# ELM_ELM_527F0000h register map
Vendor: Texas Instruments
Peripheral module from a debugger description file (folder AM261x).
Registers are 32-bit, read-only, reset values left out (the file's numbers can be read two ways) unless marked. A register's access mark holds for its fields unless they carry their own. Offsets are as the file gives them; lines under a group give offsets from that group; [hi:lo] are bit positions; {n}, {i} and the like mark numbered series; 'fields as' and 'values as' point back to an identical list; <NAME> marks a mode.

## ELM
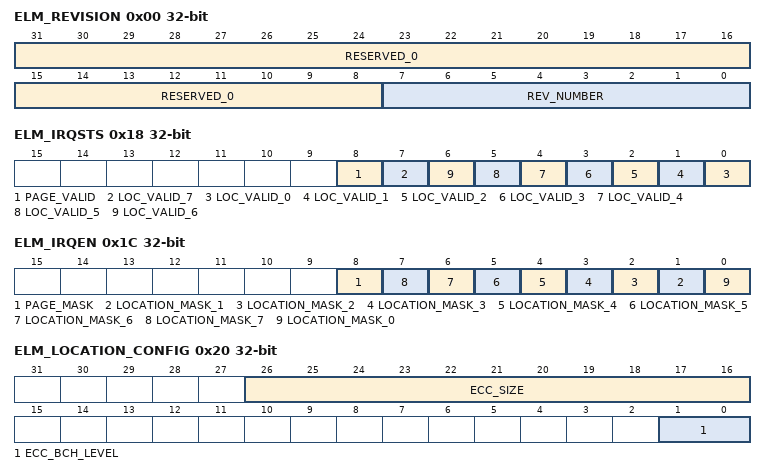
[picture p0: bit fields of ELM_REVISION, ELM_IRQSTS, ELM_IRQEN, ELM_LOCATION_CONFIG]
0x00 ELM_REVISION — This register contains the IP revision code.(A write to this register has no effect, the same as the reset).
  [31:8] RESERVED_0 — Read returns 0
  [7:0] REV_NUMBER — IP revision number [RTL] [7:4] Major revision [3:0] Minor revision
0x14 ELM_SYSSTS — Internal Reset monitoring (OCP domain)Undefined since:From HW perspective reset state is 0From SW user perspective when module is accessible is 1
  [0] RESETDONE
0x18 ELM_IRQSTS access not given — Interrupt status. This register doubles as a status register for the error location processes.
  [8] PAGE_VALID — Error location status for a full page, based on the mask definition Read 0x0: error locations invalid for all polynomials enabled in the ECC_INTERRUPT_MASK register Read 0x1: all error locations valid Write 0x0: no effect Write 0x1: clear interrupt (access R/W1TC)
  [7] LOC_VALID_7 — Error location status for syndrome polynomial 7 Read 0x0: no syndrome processed or process in progress Read 0x1: error location process completed Write 0x0: no effect Write 0x1: clear interrupt (access R/W1TC)
  [n] LOC_VALID_{n} (n=0..6) — Error location status for syndrome polynomial {n} (access R/W1TC)
0x1C ELM_IRQEN rw — Interrupt enable.
  [8] PAGE_MASK — Page interrupt mask bit0:disable interrupt1:enable interrupt
  [n] LOCATION_MASK_{n} (n=1..7) — Error location interrupt mask bit for syndrome polynomial {n}
  [0] LOCATION_MASK_0 — Error location interrupt mask bit for syndrome polynomial 00:disable interrupt1:enable interrupt
0x20 ELM_LOCATION_CONFIG rw — ECC algorithm parameters.
  [26:16] ECC_SIZE — Maximum size of the buffers for which the error location engine is used, in number of nibbles [4-bits entities]
  [1:0] ECC_BCH_LEVEL — Error correction level 0x0: 4 bits 0x1: 8 bits 0x2: 16 bits 0x3: reserved
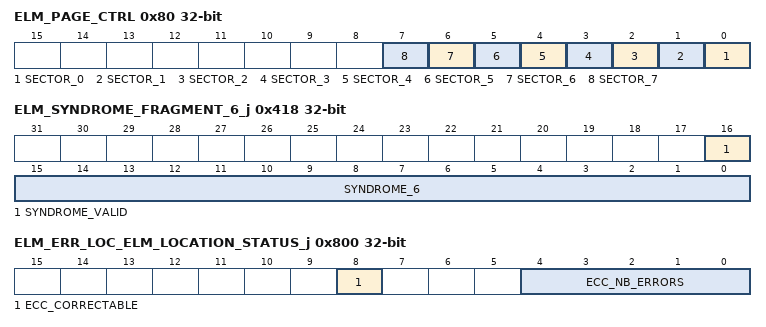
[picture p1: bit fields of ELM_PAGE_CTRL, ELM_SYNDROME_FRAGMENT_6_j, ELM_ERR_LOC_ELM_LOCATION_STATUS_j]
0x80 ELM_PAGE_CTRL rw — Page definition.
  [n] SECTOR_{n} (n=0..7) — Set to 1 if syndrome polynomial {n} is part of the page in page mode Must be 0 in continuous mode
{0x400+4i} ELM_SYNDROME_FRAGMENT_{i}_j rw (i=0..2) — Input syndrome polynomial bits {32i} to {32i+31}.
  [31:0] SYNDROME_{i} — Syndrome bits {32i} to {32i+31}
0x40C ELM_SYNDROME_FRAGMENT_3_j rw — Input syndrome polynomial bits 96 to 127
  [31:0] SYNDROME_3 — Syndrome bits 96 to 127
0x410 ELM_SYNDROME_FRAGMENT_4_j rw — Input syndrome polynomial bits 128 to 159.
  [31:0] SYNDROME_4 — Syndrome bits 128 to 159
0x414 ELM_SYNDROME_FRAGMENT_5_j rw — Input syndrome polynomial bits 160 to 191.
  [31:0] SYNDROME_5 — Syndrome bits 160 to 191
0x418 ELM_SYNDROME_FRAGMENT_6_j rw — Input syndrome polynomial bits 192 to 207.
  [16] SYNDROME_VALID — Syndrome valid bit 0x0: this syndrome polynomial should not be processed 0x1: this syndrome polynomial must be processed
  [15:0] SYNDROME_6 — Syndrome bits 192 to 207
0x800 ELM_ERR_LOC_ELM_LOCATION_STATUS_j — Exit status for the syndrome polynomial processing
  [8] ECC_CORRECTABLE — Error location process exit status 0x0: ECC error location process failed Number of errors and error locations are invalid 0x1: all errors were successfully located Number of errors and error locations are valid
  [4:0] ECC_NB_ERRORS — Number of errors detected and located
{0x880+4i} ELM_ERR_LOC_ELM_ERROR_LOCATION_{i}_j (i=0..15) — Error location register
  [12:0] ECC_ERROR_LOCATION — Error location bit address
